# CY8C5888LTI_LP097 register map
File version: 0.1
Registers are 8-bit, read-write, no defined reset value unless marked. A register's access mark holds for its fields unless they carry their own. Offsets are from the block's base; [hi:lo] are bit positions; 'fields as' and 'values as' point back to an identical list.

## NeckHandle
Base 0x00000000
0x40006528 NeckHandle_COMPARE_1 16-bit — UDB.D0 - Assigned Compare1 Value
0x40006538 NeckHandle_COMPARE_2 16-bit — UDB.D1 - Assigned Compare2 Value
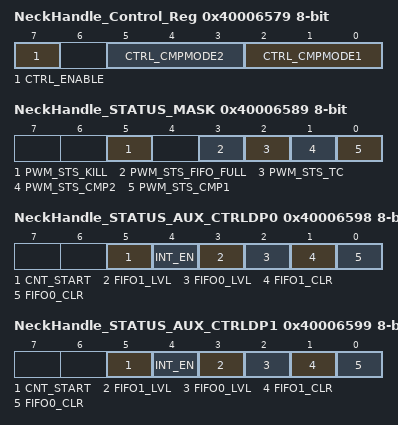
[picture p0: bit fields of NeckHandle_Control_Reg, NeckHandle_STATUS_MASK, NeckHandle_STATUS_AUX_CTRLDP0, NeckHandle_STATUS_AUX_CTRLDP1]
0x40006579 NeckHandle_Control_Reg — UDB Control Register - Assigned Control Register Value
  [7] CTRL_ENABLE — Enable the PWM
  [5:3] CTRL_CMPMODE2 — Compare mode 2
  [2:0] CTRL_CMPMODE1 — Compare mode 1
0x40006589 NeckHandle_STATUS_MASK — UDB Status bits Interrupt Mask Enable Register
  [5] PWM_STS_KILL ro — Enables the Interrupt on Kill
  [3] PWM_STS_FIFO_FULL ro — FIFO Full Status Mask
  [2] PWM_STS_TC ro — Enables the Interrupt on Terminal Count
  [1] PWM_STS_CMP2 ro — Enables the Interrupt on Compare 2
  [0] PWM_STS_CMP1 ro — Enables the Interrupt on Compare 1
0x40006598 NeckHandle_STATUS_AUX_CTRLDP0 — UDB Auxilliary Control Register
  [5] CNT_START — FIFO0 clear
    0=E_CNT_START0 (Disable counter); 1=E_CNT_START1 (Enable counter)
  [4] INT_EN
    0=E_INT_EN0 (Interrupt disabled); 1=E_INT_EN1 (Interrupt enabled)
  [3] FIFO1_LVL — FIFO level
    0=E_FIFO_LVL_0 (FIFO LVL: input mode: FIFO not full; output mode: FIFO not empty); 1=E_FIFO_LVL_1 (FIFO LVL: input mode: FIFO at least 1/2 empty; output mode: FIFO at least 1/2 full)
  [2] FIFO0_LVL — FIFO level
    values as FIFO1_LVL
  [1] FIFO1_CLR — FIFO1 clear
    0=E_FIFO_CLR_0 (Normal FIFO operation); 1=E_FIFO_CLR_1 (Clear FIFO state)
  [0] FIFO0_CLR — FIFO0 clear
    values as FIFO1_CLR
0x40006599 NeckHandle_STATUS_AUX_CTRLDP1 — UDB Auxilliary Control Register
  fields as NeckHandle_STATUS_AUX_CTRLDP0

## Left_Eyeball
Base 0x00000000
0x40006524 Left_Eyeball_COMPARE_1 16-bit — UDB.D0 - Assigned Compare1 Value
0x40006534 Left_Eyeball_COMPARE_2 16-bit — UDB.D1 - Assigned Compare2 Value
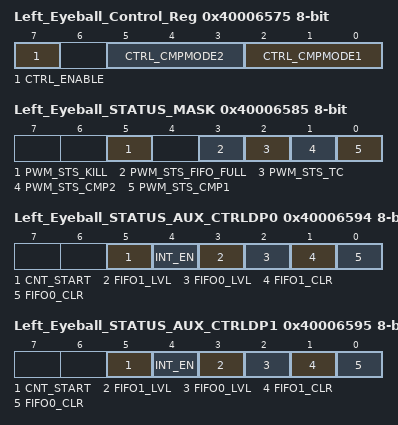
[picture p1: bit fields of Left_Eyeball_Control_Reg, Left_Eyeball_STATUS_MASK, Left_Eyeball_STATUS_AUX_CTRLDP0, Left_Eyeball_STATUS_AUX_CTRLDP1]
0x40006575 Left_Eyeball_Control_Reg — UDB Control Register - Assigned Control Register Value
  [7] CTRL_ENABLE — Enable the PWM
  [5:3] CTRL_CMPMODE2 — Compare mode 2
  [2:0] CTRL_CMPMODE1 — Compare mode 1
0x40006585 Left_Eyeball_STATUS_MASK — UDB Status bits Interrupt Mask Enable Register
  [5] PWM_STS_KILL ro — Enables the Interrupt on Kill
  [3] PWM_STS_FIFO_FULL ro — FIFO Full Status Mask
  [2] PWM_STS_TC ro — Enables the Interrupt on Terminal Count
  [1] PWM_STS_CMP2 ro — Enables the Interrupt on Compare 2
  [0] PWM_STS_CMP1 ro — Enables the Interrupt on Compare 1
0x40006594 Left_Eyeball_STATUS_AUX_CTRLDP0 — UDB Auxilliary Control Register
  [5] CNT_START — FIFO0 clear
    0=E_CNT_START0 (Disable counter); 1=E_CNT_START1 (Enable counter)
  [4] INT_EN
    0=E_INT_EN0 (Interrupt disabled); 1=E_INT_EN1 (Interrupt enabled)
  [3] FIFO1_LVL — FIFO level
    0=E_FIFO_LVL_0 (FIFO LVL: input mode: FIFO not full; output mode: FIFO not empty); 1=E_FIFO_LVL_1 (FIFO LVL: input mode: FIFO at least 1/2 empty; output mode: FIFO at least 1/2 full)
  [2] FIFO0_LVL — FIFO level
    values as FIFO1_LVL
  [1] FIFO1_CLR — FIFO1 clear
    0=E_FIFO_CLR_0 (Normal FIFO operation); 1=E_FIFO_CLR_1 (Clear FIFO state)
  [0] FIFO0_CLR — FIFO0 clear
    values as FIFO1_CLR
0x40006595 Left_Eyeball_STATUS_AUX_CTRLDP1 — UDB Auxilliary Control Register
  fields as Left_Eyeball_STATUS_AUX_CTRLDP0

## Right_Eyeball
Base 0x00000000
0x40006526 Right_Eyeball_COMPARE_1 16-bit — UDB.D0 - Assigned Compare1 Value
0x40006536 Right_Eyeball_COMPARE_2 16-bit — UDB.D1 - Assigned Compare2 Value
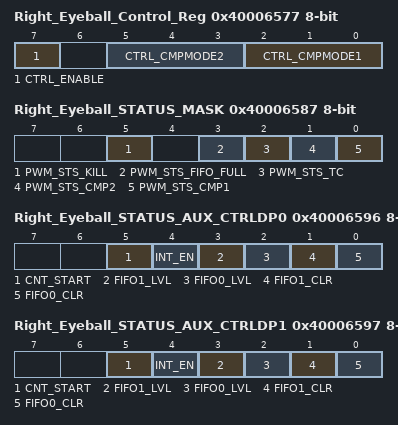
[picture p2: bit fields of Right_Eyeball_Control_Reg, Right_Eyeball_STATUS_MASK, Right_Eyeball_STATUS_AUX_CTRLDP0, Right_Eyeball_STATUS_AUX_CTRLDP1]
0x40006577 Right_Eyeball_Control_Reg — UDB Control Register - Assigned Control Register Value
  [7] CTRL_ENABLE — Enable the PWM
  [5:3] CTRL_CMPMODE2 — Compare mode 2
  [2:0] CTRL_CMPMODE1 — Compare mode 1
0x40006587 Right_Eyeball_STATUS_MASK — UDB Status bits Interrupt Mask Enable Register
  [5] PWM_STS_KILL ro — Enables the Interrupt on Kill
  [3] PWM_STS_FIFO_FULL ro — FIFO Full Status Mask
  [2] PWM_STS_TC ro — Enables the Interrupt on Terminal Count
  [1] PWM_STS_CMP2 ro — Enables the Interrupt on Compare 2
  [0] PWM_STS_CMP1 ro — Enables the Interrupt on Compare 1
0x40006596 Right_Eyeball_STATUS_AUX_CTRLDP0 — UDB Auxilliary Control Register
  [5] CNT_START — FIFO0 clear
    0=E_CNT_START0 (Disable counter); 1=E_CNT_START1 (Enable counter)
  [4] INT_EN
    0=E_INT_EN0 (Interrupt disabled); 1=E_INT_EN1 (Interrupt enabled)
  [3] FIFO1_LVL — FIFO level
    0=E_FIFO_LVL_0 (FIFO LVL: input mode: FIFO not full; output mode: FIFO not empty); 1=E_FIFO_LVL_1 (FIFO LVL: input mode: FIFO at least 1/2 empty; output mode: FIFO at least 1/2 full)
  [2] FIFO0_LVL — FIFO level
    values as FIFO1_LVL
  [1] FIFO1_CLR — FIFO1 clear
    0=E_FIFO_CLR_0 (Normal FIFO operation); 1=E_FIFO_CLR_1 (Clear FIFO state)
  [0] FIFO0_CLR — FIFO0 clear
    values as FIFO1_CLR
0x40006597 Right_Eyeball_STATUS_AUX_CTRLDP1 — UDB Auxilliary Control Register
  fields as Right_Eyeball_STATUS_AUX_CTRLDP0

## Left_Eyebrow
Base 0x00000000
0x4000642A Left_Eyebrow_COMPARE_1 16-bit — UDB.D0 - Assigned Compare1 Value
0x4000643A Left_Eyebrow_COMPARE_2 16-bit — UDB.D1 - Assigned Compare2 Value
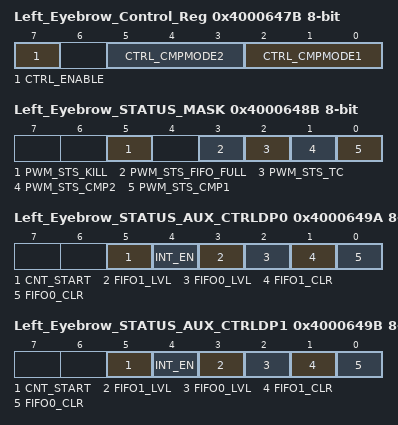
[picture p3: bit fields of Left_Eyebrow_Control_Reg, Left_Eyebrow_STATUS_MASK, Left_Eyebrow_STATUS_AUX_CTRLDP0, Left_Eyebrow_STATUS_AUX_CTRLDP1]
0x4000647B Left_Eyebrow_Control_Reg — UDB Control Register - Assigned Control Register Value
  [7] CTRL_ENABLE — Enable the PWM
  [5:3] CTRL_CMPMODE2 — Compare mode 2
  [2:0] CTRL_CMPMODE1 — Compare mode 1
0x4000648B Left_Eyebrow_STATUS_MASK — UDB Status bits Interrupt Mask Enable Register
  [5] PWM_STS_KILL ro — Enables the Interrupt on Kill
  [3] PWM_STS_FIFO_FULL ro — FIFO Full Status Mask
  [2] PWM_STS_TC ro — Enables the Interrupt on Terminal Count
  [1] PWM_STS_CMP2 ro — Enables the Interrupt on Compare 2
  [0] PWM_STS_CMP1 ro — Enables the Interrupt on Compare 1
0x4000649A Left_Eyebrow_STATUS_AUX_CTRLDP0 — UDB Auxilliary Control Register
  [5] CNT_START — FIFO0 clear
    0=E_CNT_START0 (Disable counter); 1=E_CNT_START1 (Enable counter)
  [4] INT_EN
    0=E_INT_EN0 (Interrupt disabled); 1=E_INT_EN1 (Interrupt enabled)
  [3] FIFO1_LVL — FIFO level
    0=E_FIFO_LVL_0 (FIFO LVL: input mode: FIFO not full; output mode: FIFO not empty); 1=E_FIFO_LVL_1 (FIFO LVL: input mode: FIFO at least 1/2 empty; output mode: FIFO at least 1/2 full)
  [2] FIFO0_LVL — FIFO level
    values as FIFO1_LVL
  [1] FIFO1_CLR — FIFO1 clear
    0=E_FIFO_CLR_0 (Normal FIFO operation); 1=E_FIFO_CLR_1 (Clear FIFO state)
  [0] FIFO0_CLR — FIFO0 clear
    values as FIFO1_CLR
0x4000649B Left_Eyebrow_STATUS_AUX_CTRLDP1 — UDB Auxilliary Control Register
  fields as Left_Eyebrow_STATUS_AUX_CTRLDP0

## Right_Eyebrow
Base 0x00000000
0x40006428 Right_Eyebrow_COMPARE_1 16-bit — UDB.D0 - Assigned Compare1 Value
0x40006438 Right_Eyebrow_COMPARE_2 16-bit — UDB.D1 - Assigned Compare2 Value
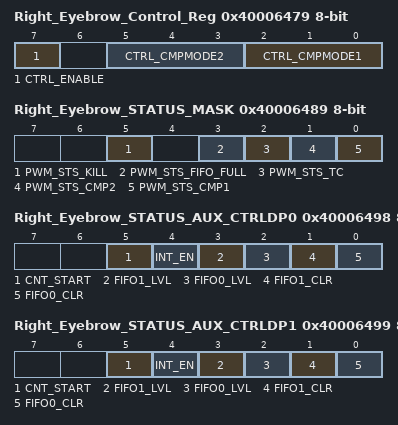
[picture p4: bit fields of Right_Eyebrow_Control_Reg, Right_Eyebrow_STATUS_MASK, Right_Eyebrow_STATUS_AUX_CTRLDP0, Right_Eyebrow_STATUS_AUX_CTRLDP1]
0x40006479 Right_Eyebrow_Control_Reg — UDB Control Register - Assigned Control Register Value
  [7] CTRL_ENABLE — Enable the PWM
  [5:3] CTRL_CMPMODE2 — Compare mode 2
  [2:0] CTRL_CMPMODE1 — Compare mode 1
0x40006489 Right_Eyebrow_STATUS_MASK — UDB Status bits Interrupt Mask Enable Register
  [5] PWM_STS_KILL ro — Enables the Interrupt on Kill
  [3] PWM_STS_FIFO_FULL ro — FIFO Full Status Mask
  [2] PWM_STS_TC ro — Enables the Interrupt on Terminal Count
  [1] PWM_STS_CMP2 ro — Enables the Interrupt on Compare 2
  [0] PWM_STS_CMP1 ro — Enables the Interrupt on Compare 1
0x40006498 Right_Eyebrow_STATUS_AUX_CTRLDP0 — UDB Auxilliary Control Register
  [5] CNT_START — FIFO0 clear
    0=E_CNT_START0 (Disable counter); 1=E_CNT_START1 (Enable counter)
  [4] INT_EN
    0=E_INT_EN0 (Interrupt disabled); 1=E_INT_EN1 (Interrupt enabled)
  [3] FIFO1_LVL — FIFO level
    0=E_FIFO_LVL_0 (FIFO LVL: input mode: FIFO not full; output mode: FIFO not empty); 1=E_FIFO_LVL_1 (FIFO LVL: input mode: FIFO at least 1/2 empty; output mode: FIFO at least 1/2 full)
  [2] FIFO0_LVL — FIFO level
    values as FIFO1_LVL
  [1] FIFO1_CLR — FIFO1 clear
    0=E_FIFO_CLR_0 (Normal FIFO operation); 1=E_FIFO_CLR_1 (Clear FIFO state)
  [0] FIFO0_CLR — FIFO0 clear
    values as FIFO1_CLR
0x40006499 Right_Eyebrow_STATUS_AUX_CTRLDP1 — UDB Auxilliary Control Register
  fields as Right_Eyebrow_STATUS_AUX_CTRLDP0
